# NVIC register map
Vendor: Texas Instruments
Peripheral module from a debugger description file (folder UCD3138R064RSM).
Registers are 32-bit, read-only, reset 0x0 unless marked. A register's access mark holds for its fields unless they carry their own. Offsets are as the file gives them; lines under a group give offsets from that group; [hi:lo] are bit positions; {n}, {i} and the like mark numbered series; 'fields as' and 'values as' point back to an identical list; <NAME> marks a mode.

## NVIC
0x00 NVIC_ISER0 — Enables or reads the enabled state of each group of 32 interrupts
  [31:0] SETENA — For SETENA[m] in NVIC_ISER*n, indicates whether interrupt 32*n + m is enabled
0x04 NVIC_ISER1 — Enables or reads the enabled state of each group of 32 interrupts
  fields as NVIC_ISER0
0x80 NVIC_ICER0 — Clears or reads the enabled state of each group of 32 interrupts
  [31:0] CLRENA — For CLRENA[m] in NVIC_ICER*n, indicates whether interrupt 32*n + m is enabled
0x84 NVIC_ICER1 — Clears or reads the enabled state of each group of 32 interrupts
  fields as NVIC_ICER0
0x100 NVIC_ISPR0 — Enables or reads the pending state of each group of 32 interrupts
  [31:0] SETPEND — For SETPEND[m] in NVIC_ISPR*n, indicates whether interrupt 32*n + m is pending
0x104 NVIC_ISPR1 — Enables or reads the pending state of each group of 32 interrupts
  fields as NVIC_ISPR0
0x180 NVIC_ICPR0 — Clears or reads the pending state of each group of 32 interrupts
  [31:0] CLRPEND — For CLRPEND[m] in NVIC_ICPR*n, indicates whether interrupt 32*n + m is pending
0x184 NVIC_ICPR1 — Clears or reads the pending state of each group of 32 interrupts
  fields as NVIC_ICPR0
0x200 NVIC_IABR0 — For each group of 32 interrupts, shows the active state of each interrupt
  [31:0] ACTIVE — For ACTIVE[m] in NVIC_IABR*n, indicates the active state for interrupt 32*n+m
0x204 NVIC_IABR1 — For each group of 32 interrupts, shows the active state of each interrupt
  fields as NVIC_IABR0
0x280 NVIC_ITNS0 rw — For each group of 32 interrupts, determines whether each interrupt targets Non-secure or Secure state
  [31:0] ITNS — For ITNS[m] in NVIC_ITNS*n, `IAAMO the target Security state for interrupt 32*n+m
0x284 NVIC_ITNS1 rw — For each group of 32 interrupts, determines whether each interrupt targets Non-secure or Secure state
  fields as NVIC_ITNS0
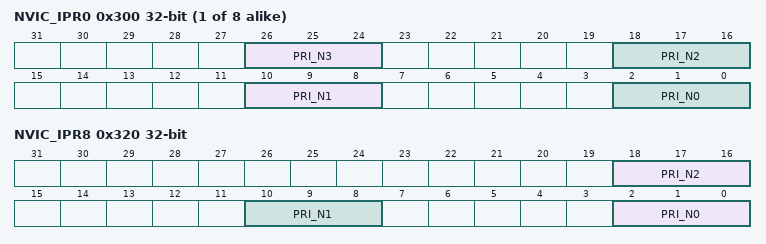
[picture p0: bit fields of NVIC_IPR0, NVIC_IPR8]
{0x300+4i} NVIC_IPR{i} (i=0..7) — Sets or reads interrupt priorities
  [26:24] PRI_N3 — For register NVIC_IPR*n, `IAAMO the priority of interrupt number 4*n+2, or is RES0 if the PE does not implement this interrupt
  [18:16] PRI_N2 — For register NVIC_IPR*n, `IAAMO the priority of interrupt number 4*n+2, or is RES0 if the PE does not implement this interrupt
  [10:8] PRI_N1 — For register NVIC_IPR*n, `IAAMO the priority of interrupt number 4*n+1, or is RES0 if the PE does not implement this interrupt
  [2:0] PRI_N0 — For register NVIC_IPR*n, `IAAMO the priority of interrupt number 4*n+0, or is RES0 if the PE does not implement this interrupt
0x320 NVIC_IPR8 — Sets or reads interrupt priorities
  [18:16] PRI_N2 — For register NVIC_IPR*n, `IAAMO the priority of interrupt number 4*n+2, or is RES0 if the PE does not implement this interrupt
  [10:8] PRI_N1 — For register NVIC_IPR*n, `IAAMO the priority of interrupt number 4*n+1, or is RES0 if the PE does not implement this interrupt
  [2:0] PRI_N0 — For register NVIC_IPR*n, `IAAMO the priority of interrupt number 4*n+0, or is RES0 if the PE does not implement this interrupt
